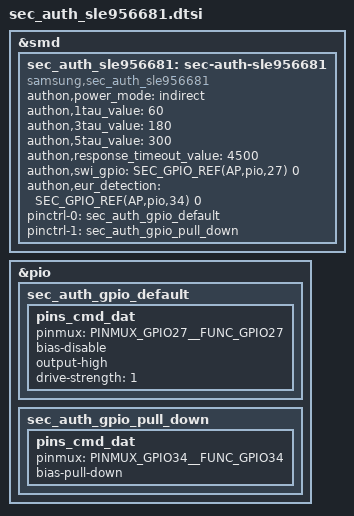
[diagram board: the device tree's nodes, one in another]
&smd {
	sec_auth_sle956681: sec-auth-sle956681 {
			status = "okay";
			compatible = "samsung,sec_auth_sle956681";

			authon,power_mode = "indirect";
			//authon,power_mode = "direct";

#if 1
			authon,1tau_value = <60>;
			authon,3tau_value = <180>;
			authon,5tau_value = <300>;
			authon,response_timeout_value = <1530>;
			authon,swi_gpio = <
				SEC_GPIO_REF(AP,pio,27) 0 /* SWI_GPIO */
#if 0
				SEC_GPIO_REF(${swi_gpio_2}) 0 /* SWI_GPIO_2 */
#endif
				>;
#endif
#if 0
			authon,1tau_value2 = <60>;
			authon,3tau_value2 = <180>;
			authon,5tau_value2 = <300>;
#endif
			};
};

/* /home/dpi/qb5_8814/workspace/P4_1716/android/kernel/kmodule/battery/suwon/battery_auth/sle956681/a17/sec_auth_sle956681.dtsi */
&pio {
	sec_auth_gpio_default: sec_auth_gpio_default {
		pins_cmd_dat {
			pinmux = <PINMUX_GPIO27__FUNC_GPIO27>;
			bias-disable;
			output-high;
			drive-strength = <1>;
		};
	};
	sec_auth_gpio_pull_down: sec_auth_gpio_pull_down {
		pins_cmd_dat {
			pinmux = <PINMUX_GPIO34__FUNC_GPIO34>;
			bias-pull-down;
		};
	};
};

&sec_auth_sle956681 {
	authon,1tau_value = <60>;
	authon,3tau_value = <180>;
	authon,5tau_value = <300>;
	authon,response_timeout_value = <4500>;
#if 1
	/*EUR_DETECTION_NODE*/
	authon,eur_detection = <SEC_GPIO_REF(AP,pio,34) 0 >;
	pinctrl-names = "default", "pull_down";
	pinctrl-0 = <&sec_auth_gpio_default>;
	pinctrl-1 = <&sec_auth_gpio_pull_down>;
#else
	pinctrl-names = "default";
	pinctrl-0 = <&sec_auth_gpio_default>;
#endif
};
